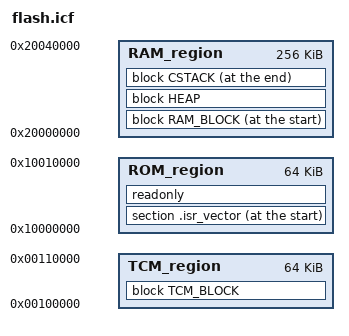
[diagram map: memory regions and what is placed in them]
/*###ICF### Section handled by ICF editor, don't touch! ****/
/*-Editor annotation file-*/
/* IcfEditorFile="$TOOLKIT_DIR$\config\ide\IcfEditor\cortex_v1_0.xml" */
/*-Specials-*/
define symbol __ICFEDIT_intvec_start__ = 0x10000000;
/*-Memory Regions-*/
define symbol __ICFEDIT_region_ROM_start__ = 0x10000000;
define symbol __ICFEDIT_region_ROM_end__   = 0x10010000;
define symbol __ICFEDIT_region_RAM_start__ = 0x20000000;
define symbol __ICFEDIT_region_RAM_end__   = 0x20040000;
define symbol __ICFEDIT_region_TCM_start__ = 0x00100000;
define symbol __ICFEDIT_region_TCM_end__   = 0x00110000;
/*-Sizes-*/
define symbol __ICFEDIT_size_cstack__ = 0xC00;
define symbol __ICFEDIT_size_heap__   = 0x0;
/**** End of ICF editor section. ###ICF###*/

define memory mem with size = 4G;
define region ROM_region      = mem:[from __ICFEDIT_region_ROM_start__   to __ICFEDIT_region_ROM_end__];
define region RAM_region      = mem:[from __ICFEDIT_region_RAM_start__   to __ICFEDIT_region_RAM_end__];
define region TCM_region      = mem:[from __ICFEDIT_region_TCM_start__   to __ICFEDIT_region_TCM_end__];

define block CSTACK    with alignment = 8, size = __ICFEDIT_size_cstack__   { };
define block HEAP      with alignment = 8, size = __ICFEDIT_size_heap__     { };

define block TCM_BLOCK with fixed order { 
                                          section .tcmBSS
                                        };

define block RAM_BLOCK with fixed order { 
                                          readwrite,
                                          section .ramTEXT
                                        };


initialize by copy { section .ramTEXT };
/*initialize by copy { section .isr_vector };*/
initialize by copy { readwrite };

do not initialize  { section .noinit };

/*place at address mem:0x10000000 { section .isr_vector };*/

place at start of ROM_region   { section .isr_vector };

place in ROM_region            { readonly };

place in TCM_region            { block TCM_BLOCK };

place at start of RAM_region   { block RAM_BLOCK };
place in RAM_region            { block HEAP };
place at end of RAM_region     { block CSTACK };
